# F28x7x_can_regs register map
Vendor: Texas Instruments
Peripheral module from a debugger description file (folder C2000).
Address unit: 16 bits
Registers are 32-bit, read-write, no defined reset value unless marked. A register's access mark holds for its fields unless they carry their own. Offsets are as the file gives them; lines under a group give offsets from that group; [hi:lo] are bit positions; {n}, {i} and the like mark numbered series; 'fields as' and 'values as' point back to an identical list; <NAME> marks a mode.

## CAN_REGS
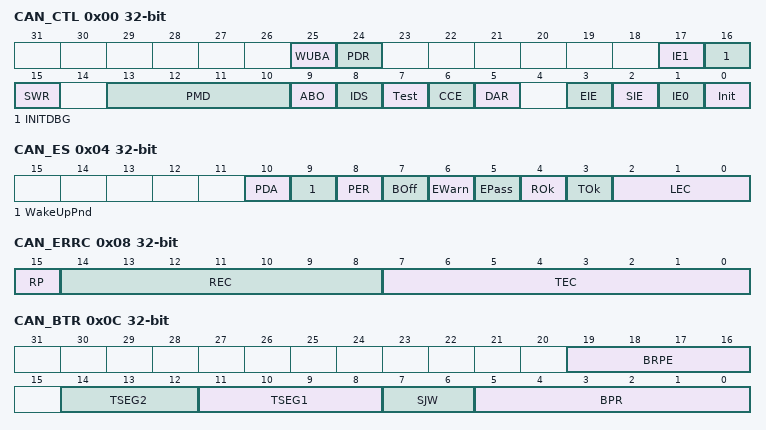
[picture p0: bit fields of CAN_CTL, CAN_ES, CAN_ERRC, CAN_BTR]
0x00 CAN_CTL — CAN Control Register
  [25] WUBA — Wake Up on Bus Activity
  [24] PDR — Power Down Request Mode
  [17] IE1 — Interrupt line 1 Enable Disabled
  [16] INITDBG — Debug Mode Status
  [15] SWR — SW Reset Enable
  [13:10] PMD — Parity on/off
  [9] ABO — Auto-Bus-On Enable
  [8] IDS — Interruption Debug Support Enable
  [7] Test — Test Mode Enable
  [6] CCE — Configuration Change Enable
  [5] DAR — Disable Automatic Retransmission
  [3] EIE — Error Interrupt Enable Disabled
  [2] SIE — Status Change Interrupt Enable Disabled
  [1] IE0 — Interrupt line 0 Enable Disabled
  [0] Init — Initialization
0x04 CAN_ES — Error and Status Register
  [10] PDA — Power down mode acknowledge
  [9] WakeUpPnd — Wake Up Pending
  [8] PER — Parity Error Detected
  [7] BOff — Bus-Off State
  [6] EWarn — Warning State
  [5] EPass — Error Passive State
  [4] ROk — Reception status Bit: This bit indicates the status of reception. The bit will be reset after the CPU reads the register.[[br]]0 No message has been successfully received since the [[br]] last time when this bit was read by the CPU. This bit is [[br]] never reset by CAN internal events.[[br]]1 A message has been successfully received since the [[br]] last time when this bit was reset by a read access of the [[br]] CPU.
  [3] TOk — Transmission status Bit: This bit indicates the status of transmission. The bit will be reset after the CPU reads the register.[[br]]0 No message has been successfully transmitted since the [[br]] last time when this bit was read by the CPU. This bit is [[br]] never reset by CAN internal events.[[br]]1 A message has been successfully transmitted (error free [[br]] and acknowledged by at least one other node) since the [[br]] last time when this bit was cleared by a read access of the [[br]] CPU.
  [2:0] LEC — Last Error Code
0x08 CAN_ERRC — Error Counter Register
  [15] RP — Receive Error Passive
  [14:8] REC — Receive Error Counter
  [7:0] TEC — Transmit Error Counter
0x0C CAN_BTR — Bit Timing Register
  [19:16] BRPE — Baud Rate Prescaler Extension
  [14:12] TSEG2 — Time segment
  [11:8] TSEG1 — Time segment
  [7:6] SJW — Synchronization Jump Width
  [5:0] BPR — Baud Rate Prescaler
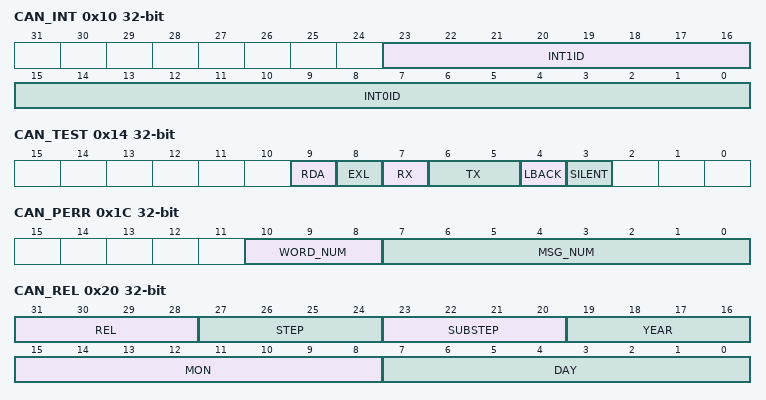
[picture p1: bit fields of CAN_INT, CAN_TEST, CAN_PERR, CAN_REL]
0x10 CAN_INT — Interrupt Register
  [23:16] INT1ID — Interrupt 1 Identifier
  [15:0] INT0ID — Interrupt Identifier
0x14 CAN_TEST — Test Register
  [9] RDA — RAM Direct Access Enable:
  [8] EXL — External Loopback Mode
  [7] RX — CANRX Pin Status
  [6:5] TX — CANTX Pin Control
  [4] LBACK — Loopback Mode
  [3] SILENT — Silent Mode
0x1C CAN_PERR — CAN Parity Error Code Register
  [10:8] WORD_NUM — Word Number
  [7:0] MSG_NUM — Message Number
0x20 CAN_REL — CAN Core Release Register
  [31:28] REL — Release
  [27:24] STEP
  [23:20] SUBSTEP
  [19:16] YEAR
  [15:8] MON — Month
  [7:0] DAY
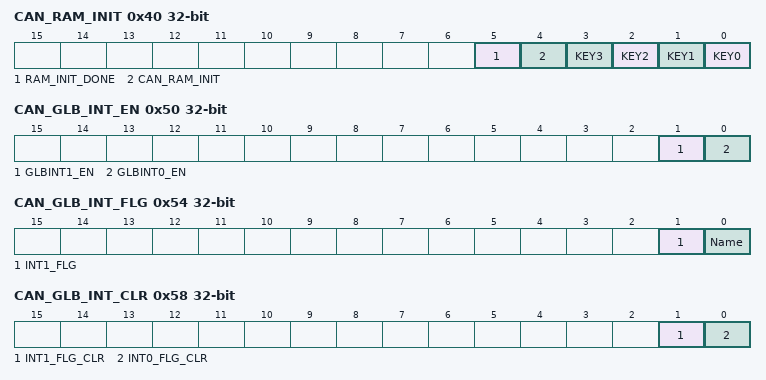
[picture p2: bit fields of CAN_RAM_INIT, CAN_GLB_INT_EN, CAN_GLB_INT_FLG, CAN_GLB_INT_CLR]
0x40 CAN_RAM_INIT — CAN RAM Initialization Register
  [5] RAM_INIT_DONE — CAN RAM initialization complete
  [4] CAN_RAM_INIT — Initialize CAN Mailbox RAM
  [n] KEY{n} (n=0..3)
0x50 CAN_GLB_INT_EN — CAN Global Interrupt Enable Register
  [1] GLBINT1_EN — Global Interrupt Enable for CAN INT1
  [0] GLBINT0_EN — Global Interrupt Enable for CAN INT0
0x54 CAN_GLB_INT_FLG — CAN Global Interrupt Flag Register
  [1] INT1_FLG — Global Interrupt Flag for CAN INT1
  [0] Name — Global Interrupt Flag for CAN INT0
0x58 CAN_GLB_INT_CLR — CAN Global Interrupt Clear Register
  [1] INT1_FLG_CLR — Global Interrupt flag clear for CAN INT1
  [0] INT0_FLG_CLR — Global Interrupt flag clear for CAN INT0
0x80 CAN_ABOTR — Auto-Bus-On Time Register
  [31:0] ABO_Time — Auto-Bus-On Timer
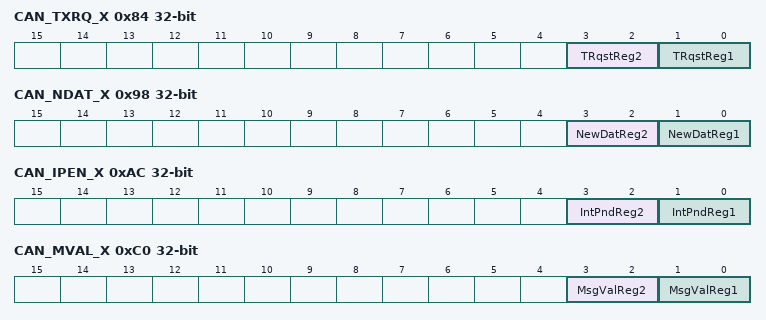
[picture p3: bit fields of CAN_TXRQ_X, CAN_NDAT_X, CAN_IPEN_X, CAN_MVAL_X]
0x84 CAN_TXRQ_X — CAN Transmission Request X Register
  [3:2] TRqstReg2 — Transmit Request Register 2 flag: [[br]]Bit 2 represents byte 2 of CAN_TXRQ_21. If one or more bits in that [[br]]byte are set, then bit 2 will be set.[[br]]Bit 3 represents byte 3 of CAN_TXRQ_21 Register. If one or more bits in that byte are set, then bit 3 will be set.
  [1:0] TRqstReg1 — Transmit Request Register 1 flag: With these bits, the CPU can [[br]]detect if one or more bits in the CAN Transmission Request 2_1 [[br]]Register (CAN_TXRQ_21) is set. Each register bit represents a group [[br]]of eight mailboxes. If at least one of the TxRqst bits of these message [[br]]objects are set, the corresponding bit in the Transmission Request X [[br]]Register will be set. [[br]]Bit 0 represents byte 0 of CAN_TXRQ_21 Register. If one or more bits [[br]]in that byte are set, then bit 0 will be set.[[br]]Bit 1 represents byte 1 of CAN_TXRQ_21 Register. If one or more bits [[br]]in that byte are set, then bit 1 will be set.
0x88 CAN_TXRQ_21 — CAN Transmission Request 2_1 Register
  [31:0] TRqst — Transmission Request Bits (for all message objects)[[br]][[br]] 0 No transmission has been requested for this message object.[[br]][[br]] 1 The transmission of this message object is requested and is not yet done.
0x98 CAN_NDAT_X — CAN New Data X Register
  [3:2] NewDatReg2 — New Data Register 2
  [1:0] NewDatReg1 — New Data Register 1
0x9C CAN_NDAT_21 — CAN New Data 2_1 Register
  [31:0] NewDat — New Data Bits
0xAC CAN_IPEN_X — CAN Interrupt Pending X Register
  [3:2] IntPndReg2 — Interrupt Pending Register 2
  [1:0] IntPndReg1 — Interrupt Pending Register 1
0xB0 CAN_IPEN_21 — CAN Interrupt Pending 2_1 Register
  [31:0] IntPnd — Interrupt Pending
0xC0 CAN_MVAL_X — CAN Message Valid X Register
  [3:2] MsgValReg2 — Message Valid Register 2
  [1:0] MsgValReg1 — Message Valid Register 1
0xC4 CAN_MVAL_21 — CAN Message Valid 2_1 Register
  [31:0] MsgValReg — Message Valid Bits
0xD8 CAN_IP_MUX21 — CAN Interrupt Multiplexer 2_1 Register
  [31:0] IntMu — Interrupt Mux bits: The IntMux flag determines for each mailbox, which of the two interrupt lines (CANn_INT0 or CANn_INT1) will be asserted when the IntPnd of this mailbox is set. [[br]][[br]]0 CANn_INT0 line is active if corresponding IntPnd flag is one.[[br]]1 CANn_INT1 line is active if corresponding IntPnd flag is one.
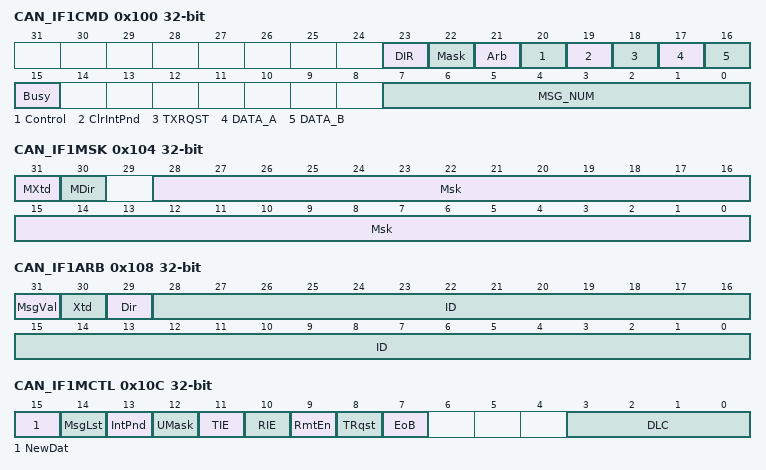
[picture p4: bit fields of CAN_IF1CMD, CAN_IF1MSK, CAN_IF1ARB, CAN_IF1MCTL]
0x100 CAN_IF1CMD — IF1 Command Register
  [23] DIR — Write/Read Direction
  [22] Mask — Access Mask Bits
  [21] Arb — Access Arbitration Bits
  [20] Control — Access Control Bits
  [19] ClrIntPnd — Clear Interrupt Pending Bit
  [18] TXRQST — Access Transmission Request Bit
  [17] DATA_A — Access Data Bytes 0-3
  [16] DATA_B — Access Data Bytes 4-7
  [15] Busy — Busy Flag
  [7:0] MSG_NUM — Message Number
0x104 CAN_IF1MSK — IF1 Mask Register
  [31] MXtd — Mask Extended Identifier
  [30] MDir — Mask Message Direction
  [28:0] Msk — Identifier Mask
0x108 CAN_IF1ARB — IF1 Arbitration Register
  [31] MsgVal — Message Valid
  [30] Xtd — Extended Identifier
  [29] Dir — Message Direction
  [28:0] ID — `
0x10C CAN_IF1MCTL — IF1 Message Control Register
  [15] NewDat — New Data
  [14] MsgLst — Message Lost
  [13] IntPnd — Interrupt Pending
  [12] UMask — Use Acceptance Mask
  [11] TIE — Transmit Interrupt Enable [[br]][[br]]0 IntPnd will not be triggered after the successful transmission of a frame. [[br]][[br]]1 IntPnd will be triggered after the successful transmission of a frame.[[br]][[br]]Note: This bit is write protected by Busy bit.
  [10] RIE — Receive Interrupt Enable [[br]][[br]]0 IntPnd will not be triggered after the successful reception of a frame. [[br]][[br]]1 IntPnd will be triggered after the successful reception of a frame.[[br]][[br]]Note: This bit is write protected by Busy bit.
  [9] RmtEn — Remote Enable
  [8] TRqst — Transmit Request [[br]][[br]]0 This message object is not waiting for a transmission. [[br]][[br]]1 The transmission of this message object is requested and is not yet done.[[br]][[br]]Note: This bit is write protected by Busy bit.
  [7] EoB — End of Block
  [3:0] DLC — Data length code
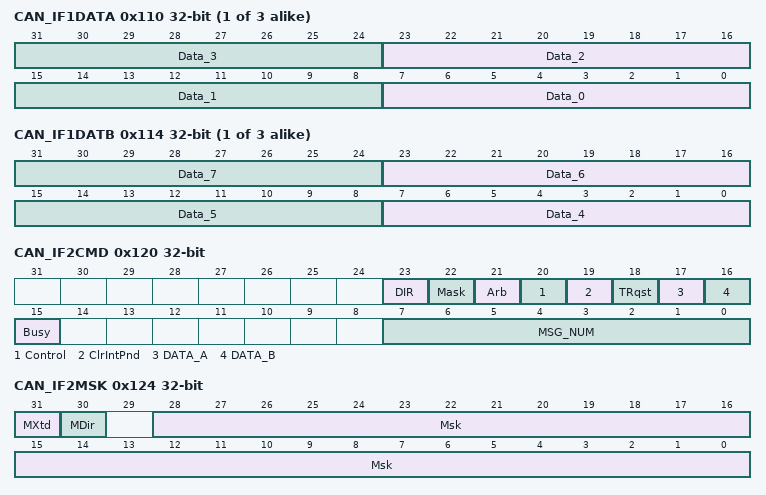
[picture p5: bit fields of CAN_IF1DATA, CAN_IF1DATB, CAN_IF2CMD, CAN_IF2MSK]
{0xF0+0x20*i} CAN_IF{i}DATA (i=1..3) — IF{i} Data A Register
  [8n+7:8n] Data_{n} (n=0..3) — Data Byte {n}
{0xF4+0x20*i} CAN_IF{i}DATB (i=1..3) — IF{i} Data B Register
  [8n-25:8n-32] Data_{n} (n=4..7) — Data Byte {n}
0x120 CAN_IF2CMD — IF2 Command Register
  [23] DIR — Write/Read Direction
  [22] Mask — Access Mask Bits
  [21] Arb — Access Arbitration Bits
  [20] Control — Access Control Bits
  [19] ClrIntPnd — Clear Interrupt Pending Bit
  [18] TRqst — Access Transmission Request Bit [[br]][[br]]0 Direction = Read: NewDat bit will not be changed. Direction = Write: TxRqst/NewDat bit will be handled according to the Control bit. [[br]][[br]]1 Direction = Read: Clears NewDat bit in the message object. Direction = Write: Sets TxRqst/NewDat in message object.[[br]][[br]] Note: If a CAN transmission is requested by setting TxRqst/NewDat in this register, the TxRqst/NewDat bits in the message object will be set to one independent of the values in IF1/IF2 Message Control Register. [[br]][[br]]Note: A read access to a message object can be combined with the reset of the control bits IntPnd and NewDat. The values of these bits transferred to the IF1/IF2 Message Control Register always reflect the status before resetting them.[[br]][[br]]Note: This bit is write protected by Busy bit.
  [17] DATA_A — Access Data Bytes 0-3
  [16] DATA_B — Access Data Bytes 4-7
  [15] Busy — Busy Flag
  [7:0] MSG_NUM — Message Number
0x124 CAN_IF2MSK — IF2 Mask Register
  fields as CAN_IF1MSK
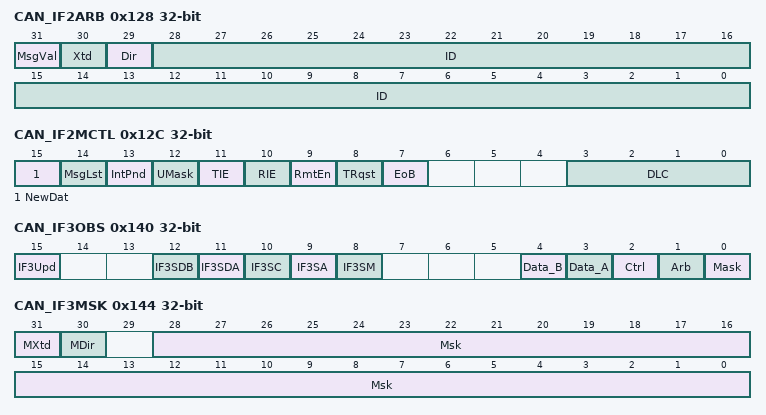
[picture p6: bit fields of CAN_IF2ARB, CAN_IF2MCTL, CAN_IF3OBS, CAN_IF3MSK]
0x128 CAN_IF2ARB — IF2 Arbitration Register
  [31] MsgVal — Message Valid
  [30] Xtd — Extended Identifier
  [29] Dir — Message Direction
  [28:0] ID — Message Identifier
0x12C CAN_IF2MCTL — IF2 Message Control Register
  fields as CAN_IF1MCTL
0x140 CAN_IF3OBS — IF3 Observation Register
  [15] IF3Upd — IF3 Update Data
  [12] IF3SDB — IF3 Status of Data B read access
  [11] IF3SDA — IF3 Status of Data A read access
  [10] IF3SC — IF3 Status of Control bits read access
  [9] IF3SA — IF3 Status of Arbitration data read access
  [8] IF3SM — IF3 Status of Mask data read access
  [4] Data_B — Data B read observation
  [3] Data_A — Data A read observation
  [2] Ctrl — Ctrl read observation
  [1] Arb — Arbitration data read observation
  [0] Mask — Mask data read observation
0x144 CAN_IF3MSK — IF3 Mask Register
  [31] MXtd — Mask Extended Identifier
  [30] MDir — Mask Message Direction
  [28:0] Msk — Mask
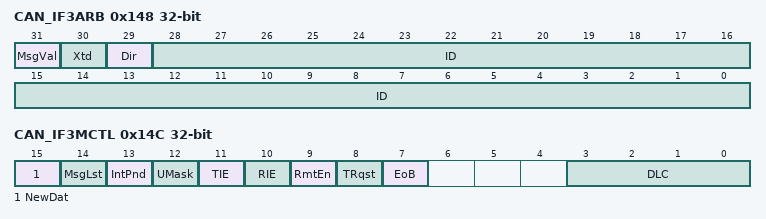
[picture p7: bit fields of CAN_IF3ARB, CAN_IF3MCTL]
0x148 CAN_IF3ARB — IF3 Arbitration Register
  fields as CAN_IF2ARB
0x14C CAN_IF3MCTL — IF3 Message Control Register
  [15] NewDat — New Data
  [14] MsgLst — Message Lost
  [13] IntPnd — Interrupt Pending
  [12] UMask — Use Acceptance Mask
  [11] TIE — Transmit Interrupt Enable [[br]][[br]]0 IntPnd will not be triggered after the successful transmission of a frame. [[br]][[br]]1 IntPnd will be triggered after the successful transmission of a frame.
  [10] RIE — Receive Interrupt Enable [[br]][[br]]0 IntPnd will not be triggered after the successful reception of a frame. [[br]][[br]]1 IntPnd will be triggered after the successful reception of a frame.
  [9] RmtEn — Remote Enable
  [8] TRqst — Transmit Request [[br]][[br]]0 This message object is not waiting for a transmission. [[br]][[br]]1 The transmission of this message object is requested and is not yet done.
  [7] EoB — End of Block
  [3:0] DLC — Data length code
0x160 CAN_IF3UPD — IF3 Update Enable Register
  [31:0] IF3UpdEn — IF3 Update Enabled
